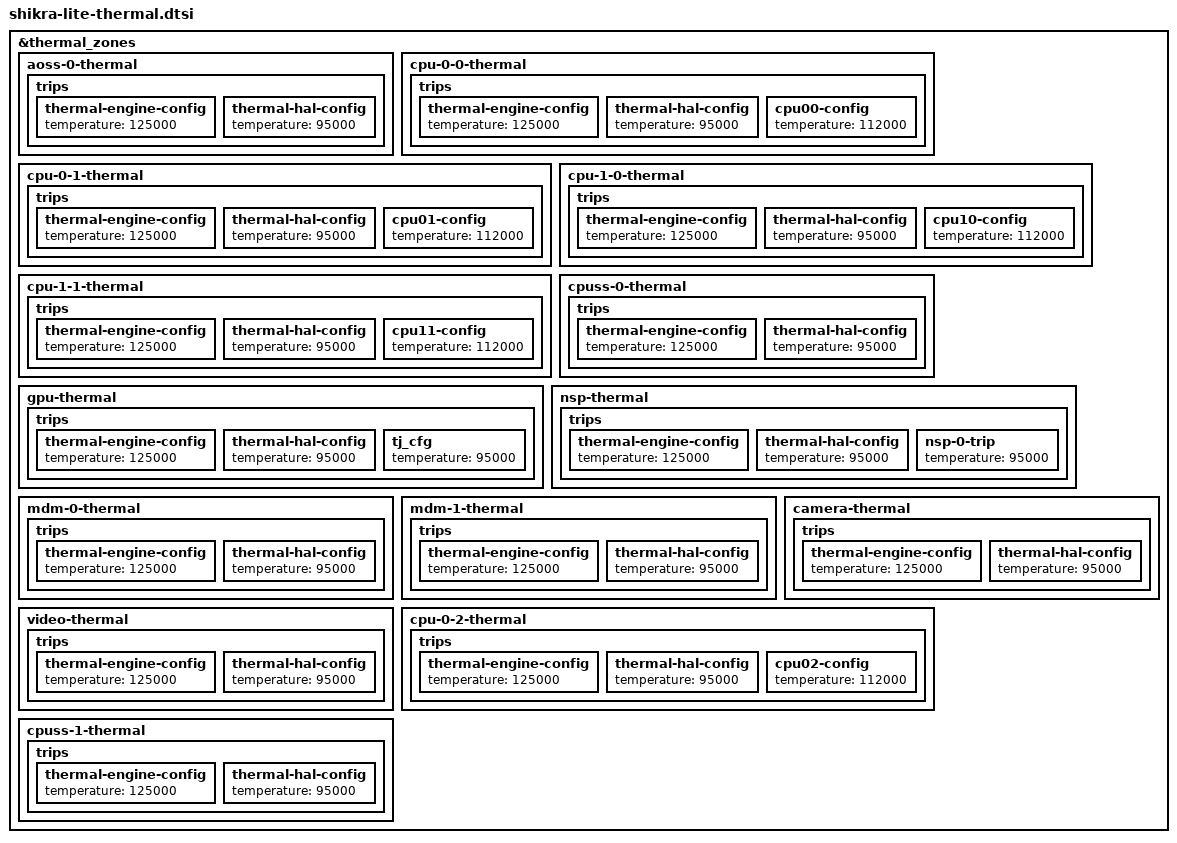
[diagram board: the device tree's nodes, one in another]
// SPDX-License-Identifier: BSD-3-Clause
/*
 * Copyright (c) Qualcomm Technologies, Inc. and/or its subsidiaries.
 */

&thermal_zones {
	aoss-0-thermal {
		trips {
			thermal-engine-config {
				temperature = <125000>;
			};

			thermal-hal-config {
				temperature = <95000>;
			};
		};
	};

	cpu-0-0-thermal {
		trips {
			thermal-engine-config {
				temperature = <125000>;
			};

			thermal-hal-config {
				temperature = <95000>;
			};

			cpu00-config {
				temperature = <112000>;
			};
		};
	};

	cpu-0-1-thermal {
		trips {
			thermal-engine-config {
				temperature = <125000>;
			};

			thermal-hal-config {
				temperature = <95000>;
			};

			cpu01-config {
				temperature = <112000>;
			};
		};
	};

	cpu-1-0-thermal {
		trips {
			thermal-engine-config {
				temperature = <125000>;
			};

			thermal-hal-config {
				temperature = <95000>;
			};

			cpu10-config {
				temperature = <112000>;
			};
		};
	};

	cpu-1-1-thermal {
		trips {
			thermal-engine-config {
				temperature = <125000>;
			};

			thermal-hal-config {
				temperature = <95000>;
			};

			cpu11-config {
				temperature = <112000>;
			};
		};
	};

	cpuss-0-thermal {
		trips {
			thermal-engine-config {
				temperature = <125000>;
			};

			thermal-hal-config {
				temperature = <95000>;
			};
		};
	};

	gpu-thermal {
		trips {
			thermal-engine-config {
				temperature = <125000>;
			};

			thermal-hal-config {
				temperature = <95000>;
			};

			tj_cfg {
				temperature = <95000>;
			};
		};
	};

	nsp-thermal {
		trips {
			thermal-engine-config {
				temperature = <125000>;
			};

			thermal-hal-config {
				temperature = <95000>;
			};

			nsp-0-trip {
				temperature = <95000>;
			};
		};
	};

	mdm-0-thermal {
		trips {
			thermal-engine-config {
				temperature = <125000>;
			};

			thermal-hal-config {
				temperature = <95000>;
			};
		};
	};

	mdm-1-thermal {
		trips {
			thermal-engine-config {
				temperature = <125000>;
			};

			thermal-hal-config {
				temperature = <95000>;
			};
		};
	};

	camera-thermal {
		trips {
			thermal-engine-config {
				temperature = <125000>;
			};

			thermal-hal-config {
				temperature = <95000>;
			};
		};
	};

	video-thermal {
		trips {
			thermal-engine-config {
				temperature = <125000>;
			};

			thermal-hal-config {
				temperature = <95000>;
			};
		};
	};

	cpu-0-2-thermal {
		trips {
			thermal-engine-config {
				temperature = <125000>;
			};

			thermal-hal-config {
				temperature = <95000>;
			};

			cpu02-config {
				temperature = <112000>;
			};
		};
	};

	cpuss-1-thermal {
		trips {
			thermal-engine-config {
				temperature = <125000>;
			};

			thermal-hal-config {
				temperature = <95000>;
			};
		};
	};
};
